# ATSAM4LC2C device description
Architecture: CORTEX-M4; Family: SAM4; Series: SAM4L
Registers are 32-bit, read-write, reset 0x0 unless marked. A register's access mark holds for its fields unless they carry their own. Offsets are from the block's base; [hi:lo] are bit positions; {n}, {i} and the like mark numbered series.

## WDT — Watchdog Timer
Instances: WDT 0x400F0C00
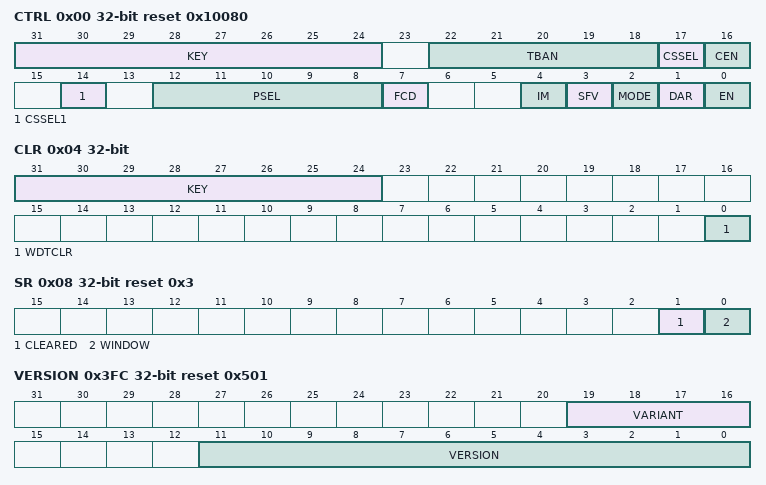
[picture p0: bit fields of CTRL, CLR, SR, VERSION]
0x00 CTRL reset 0x10080 — Control Register
  [31:24] KEY
  [22:18] TBAN — TBAN Prescale Select
  [17] CSSEL — Clock Source Selection0
  [16] CEN — Clock Enable
  [14] CSSEL1 — Clock Source Selection1
  [12:8] PSEL — Timeout Prescale Select
  [7] FCD — WDT Fuse Calibration Done
  [4] IM — WDT Interruput Mode
  [3] SFV — WDT Store Final Value
  [2] MODE — WDT Mode
  [1] DAR — WDT Disable After Reset
  [0] EN — WDT Enable
    0=WDT is disabled; 1=WDT is enabled
0x04 CLR wo — Clear Register
  [31:24] KEY
  [0] WDTCLR — Clear WDT counter
0x08 SR ro reset 0x3 — Status Register
  [1] CLEARED — WDT cleared
  [0] WINDOW — WDT in window
0x0C IER wo (atomic set of IMR) — Interrupt Enable Register
  [2] WINT — Watchdog Interrupt
0x10 IDR wo (atomic clear of IMR) — Interrupt Disable Register
  [2] WINT — Watchdog Interrupt
0x14 IMR ro — Interrupt Mask Register
  [2] WINT — Watchdog Interrupt
0x18 ISR ro — Interrupt Status Register
  [2] WINT — Watchdog Interrupt
0x1C ICR wo (atomic clear of ISR) — Interrupt Clear Register
  [2] WINT — Watchdog Interrupt
0x3FC VERSION ro reset 0x501
  [19:16] VARIANT — Variant number
  [11:0] VERSION — Version number

## SysTick — System timer
Instances: SysTick 0xE000E010
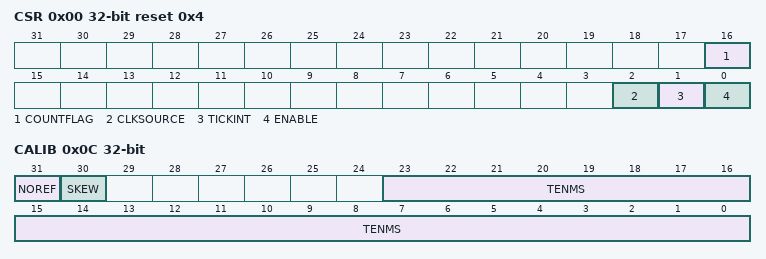
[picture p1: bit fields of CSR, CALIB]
0x00 CSR access not given reset 0x4 — SysTick Control and Status Register
  [16] COUNTFLAG
  [2] CLKSOURCE
    0=external clock; 1=processor clock
  [1] TICKINT
    0=counting down to 0 does not assert the SysTick exception request; 1=counting down to 0 asserts the SysTick exception request
  [0] ENABLE
    0=counter disabled; 1=counter enabled
0x04 RVR access not given — SysTick Reload Value Register
  [23:0] RELOAD — Value to load into the SysTick Current Value Register when the counter reaches 0
0x08 CVR access not given — SysTick Current Value Register
  [23:0] CURRENT — Current value at the time the register is accessed
0x0C CALIB access not given — SysTick Calibration Value Register
  [31] NOREF
    0=The reference clock is provided; 1=The reference clock is not provided
  [30] SKEW
    0=10ms calibration value is exact; 1=10ms calibration value is inexact, because of the clock frequency
  [23:0] TENMS — Reload value to use for 10ms timing

## NVIC — Nested Vectored Interrupt Controller
Instances: NVIC 0xE000E100
{0x0+4i} NVICISER{i} access not given (i=0..3) — Interrupt Set Enable Register n
  [31:0] SETENA — Interrupt set enable bits
{0x80+4i} NVICICER{i} access not given (i=0..3) — Interrupt Clear Enable Register n
  [31:0] CLRENA — Interrupt clear-enable bits
{0x100+4i} NVICISPR{i} access not given (i=0..3) — Interrupt Set Pending Register n
  [31:0] SETPEND — Interrupt set-pending bits
{0x180+4i} NVICICPR{i} access not given (i=0..3) — Interrupt Clear Pending Register n
  [31:0] CLRPEND — Interrupt clear-pending bits
{0x200+4i} NVICIABR{i} access not given (i=0..3) — Interrupt Active bit Register n
  [31:0] ACTIVE — Interrupt active flags
{0x300+i} NVICIP{i} 8-bit access not given (i=0..105) — Interrupt Priority Register n
  [7:0] PRI{i} — Priority of interrupt {i}
0xE00 NVICSTIR access not given — Software Trigger Interrupt Register
  [8:0] INTID — Interrupt ID of the interrupt to trigger, in the range 0-239. For example, a value of 0x03 specifies interrupt IRQ3.

## MPU — Memory Protection Unit
Instances: MPU 0xE000ED90
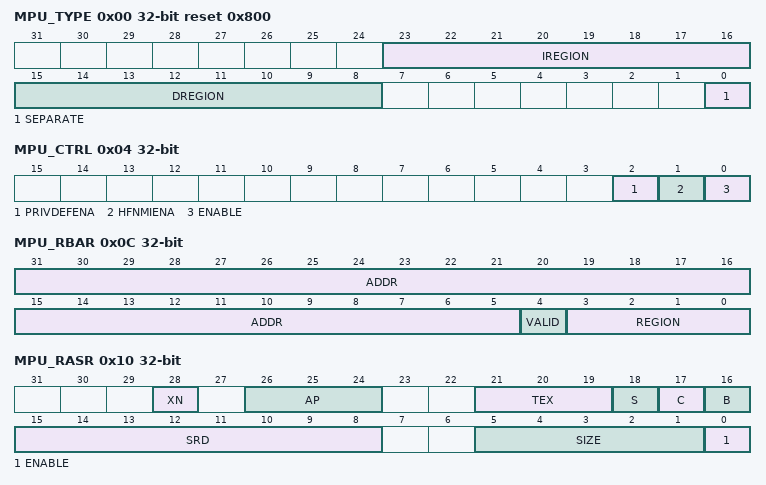
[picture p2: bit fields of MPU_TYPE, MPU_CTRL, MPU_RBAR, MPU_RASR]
0x00 MPU_TYPE ro reset 0x800
  [23:16] IREGION — Indicates the number of supported MPU data regions.
  [15:8] DREGION — Indicates the number of supported MPU instruction regions.
  [0] SEPARATE — Indicates support for unified or separate instruction and date memory maps.
0x04 MPU_CTRL — MPU Control Register
  [2] PRIVDEFENA — Enables privileged software access to the default memory map.
  [1] HFNMIENA — Enables the operation of MPU during hard fault, NMI, and FAULTMASK handlers.
  [0] ENABLE — Enables the MPU
0x08 MPU_RNR — MPU Region Number Register
  [7:0] REGION — Indicates the MPU region referenced by the MPU_RBAR and MPU_RASR registers.
0x0C MPU_RBAR — MPU Region Base Address Register
  [31:5] ADDR — Region base address field.
  [4] VALID — MPU Region Number valid bit.
  [3:0] REGION — MPU region field.
0x10 MPU_RASR — MPU Region Attribute and Size Register
  [28] XN — Instruction access disable bit.
  [26:24] AP — Access permission field.
  [21:19] TEX — MPU access permission attributes.
  [18] S — Shareable bit.
  [17] C — MPU access permission attributes.
  [16] B — MPU access permission attributes.
  [15:8] SRD — Subregion disable bits.
  [5:1] SIZE — Specifies the size of the MPU protection region.
  [0] ENABLE — Region enable bit.
